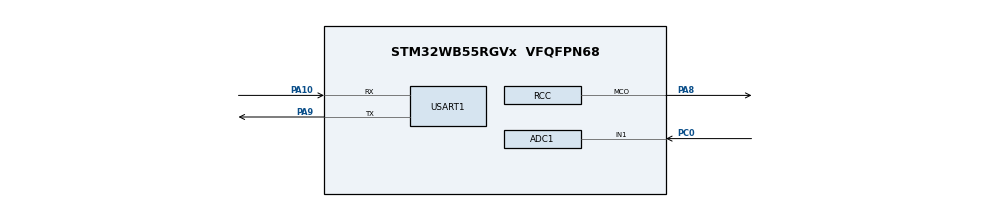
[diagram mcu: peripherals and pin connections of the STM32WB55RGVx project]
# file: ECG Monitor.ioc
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ADC1.Channel-2\#ChannelRegularConversion=ADC_CHANNEL_1
ADC1.ContinuousConvMode=ENABLE
ADC1.DataAlign=ADC_DATAALIGN_RIGHT
ADC1.NbrOfConversion=1
ADC1.NbrOfConversionFlag=1
ADC1.OffsetNumber-2\#ChannelRegularConversion=ADC_OFFSET_NONE
ADC1.Overrun=ADC_OVR_DATA_OVERWRITTEN
ADC1.Rank-2\#ChannelRegularConversion=1
ADC1.Resolution=ADC_RESOLUTION_12B
ADC1.SamplingTime-2\#ChannelRegularConversion=ADC_SAMPLETIME_2CYCLES_5
ADC1.master=1
Dma.ADC1.0.Direction=DMA_PERIPH_TO_MEMORY
Dma.ADC1.0.EventEnable=DISABLE
Dma.ADC1.0.Instance=DMA1_Channel1
Dma.ADC1.0.MemDataAlignment=DMA_MDATAALIGN_HALFWORD
Dma.ADC1.0.MemInc=DMA_MINC_ENABLE
Dma.ADC1.0.Mode=DMA_CIRCULAR
Dma.ADC1.0.PeriphDataAlignment=DMA_PDATAALIGN_HALFWORD
Dma.ADC1.0.PeriphInc=DMA_PINC_DISABLE
Dma.ADC1.0.Polarity=HAL_DMAMUX_REQ_GEN_RISING
Dma.ADC1.0.Priority=DMA_PRIORITY_LOW
Dma.ADC1.0.RequestNumber=1
Dma.ADC1.0.SignalID=NONE
Dma.ADC1.0.SyncEnable=DISABLE
Dma.ADC1.0.SyncPolarity=HAL_DMAMUX_SYNC_NO_EVENT
Dma.ADC1.0.SyncRequestNumber=1
Dma.ADC1.0.SyncSignalID=NONE
Dma.Request0=ADC1
Mcu.Family=STM32WB
Mcu.Name=STM32WB55RGVx
Mcu.Package=VFQFPN68
NVIC.ADC1_IRQn=true\:0\:0\:false\:false\:true\:true\:true\:true
NVIC.DMA1_Channel1_IRQn=true\:0\:0\:false\:false\:true\:false\:true\:true
NVIC.PriorityGroup=NVIC_PRIORITYGROUP_4
OSC_IN.Mode=HSE-External-Oscillator
OSC_IN.Signal=RCC_OSC_IN
OSC_OUT.Mode=HSE-External-Oscillator
OSC_OUT.Signal=RCC_OSC_OUT
PA10.Mode=Asynchronous
PA10.Signal=USART1_RX
PA8.Mode=Clock-out
PA8.Signal=RCC_MCO
PA9.Mode=Asynchronous
PA9.Signal=USART1_TX
PC0.Signal=ADCx_IN1
ProjectManager.HeapSize=0x200
ProjectManager.StackSize=0x400
ProjectManager.TargetToolchain=STM32CubeIDE
RCC.ADCFreq_Value=48000000
RCC.AHBFreq_Value=32000000
RCC.APB1Freq_Value=32000000
RCC.APB1TimFreq_Value=32000000
RCC.APB2Freq_Value=32000000
RCC.APB2TimFreq_Value=32000000
RCC.APB3Freq_Value=4000000
RCC.CortexFreq_Value=32000000
RCC.HCLKFreq_Value=32000000
RCC.HSE_VALUE=8000000
RCC.HSI48_VALUE=48000000
RCC.HSI_VALUE=16000000
RCC.LSE_VALUE=32768
RCC.PLLN=24
RCC.PLLR=RCC_PLLR_DIV3
RCC.PLLSAI1N=24
RCC.RCC_MCO1Source=RCC_MCO1SOURCE_HSE
RCC.SYSCLKFreq_VALUE=32000000
RCC.SYSCLKSource=RCC_SYSCLKSOURCE_PLLCLK
RCC.USBFreq_Value=48000000
RCC.VCOOutputFreq_Value=96000000
SH.ADCx_IN1.0=ADC1_IN1,IN1-Single-Ended
USART1.VirtualMode-Asynchronous=VM_ASYNC
VP_MEMORYMAP_VS_MEMORYMAP.Mode=CurAppReg
board=custom

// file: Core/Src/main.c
/* USER CODE BEGIN Header */
/**
  ******************************************************************************
  * @file           : main.c
  * @brief          : Main program body
  ******************************************************************************
  * @attention
  *
  * Copyright (c) 2026 STMicroelectronics.
  * All rights reserved.
  *
  * This software is licensed under terms that can be found in the LICENSE file
  * in the root directory of this software component.
  * If no LICENSE file comes with this software, it is provided AS-IS.
  *
  ******************************************************************************
  */
/* USER CODE END Header */
#include "main.h"

/* USER CODE BEGIN Includes */
#include <stdio.h>
/* USER CODE END Includes */

ADC_HandleTypeDef hadc1;
DMA_HandleTypeDef hdma_adc1;

UART_HandleTypeDef huart1;

/* USER CODE BEGIN PV */
uint16_t AD_RES = 0;
/* USER CODE END PV */

void SystemClock_Config(void);
void PeriphCommonClock_Config(void);
static void MX_GPIO_Init(void);
static void MX_DMA_Init(void);
static void MX_ADC1_Init(void);
static void MX_USART1_UART_Init(void);

int main(void)
{

  /* MCU Configuration--------------------------------------------------------*/

  /* Reset of all peripherals, Initializes the Flash interface and the Systick. */
  HAL_Init();

  /* Configure the system clock */
  SystemClock_Config();

  /* Configure the peripherals common clocks */
  PeriphCommonClock_Config();

  /* Initialize all configured peripherals */
  MX_GPIO_Init();
  MX_DMA_Init();
  MX_ADC1_Init();
  MX_USART1_UART_Init();
  /* USER CODE BEGIN 2 */
  HAL_ADCEx_Calibration_Start(&hadc1, 0);
  HAL_ADC_Start(&hadc1);
  /* USER CODE END 2 */

  /* Infinite loop */
  /* USER CODE BEGIN WHILE */
  while (1)
  {
	  AD_RES = HAL_ADC_GetValue(&hadc1);
	  //HAL_UART_Transmit(&huart1, &AD_RES, sizeof(AD_RES), 100);
	  HAL_Delay(1);
    /* USER CODE END WHILE */

  }
}

void SystemClock_Config(void)
{
  RCC_OscInitTypeDef RCC_OscInitStruct = {0};
  RCC_ClkInitTypeDef RCC_ClkInitStruct = {0};

  /** Configure the main internal regulator output voltage
  */
  __HAL_PWR_VOLTAGESCALING_CONFIG(PWR_REGULATOR_VOLTAGE_SCALE1);

  /** Initializes the RCC Oscillators according to the specified parameters
  * in the RCC_OscInitTypeDef structure.
  */
  RCC_OscInitStruct.OscillatorType = RCC_OSCILLATORTYPE_HSI|RCC_OSCILLATORTYPE_HSE
                              |RCC_OSCILLATORTYPE_MSI;
  RCC_OscInitStruct.HSEState = RCC_HSE_ON;
  RCC_OscInitStruct.HSIState = RCC_HSI_ON;
  RCC_OscInitStruct.MSIState = RCC_MSI_ON;
  RCC_OscInitStruct.HSICalibrationValue = RCC_HSICALIBRATION_DEFAULT;
  RCC_OscInitStruct.MSICalibrationValue = RCC_MSICALIBRATION_DEFAULT;
  RCC_OscInitStruct.MSIClockRange = RCC_MSIRANGE_6;
  RCC_OscInitStruct.PLL.PLLState = RCC_PLL_ON;
  RCC_OscInitStruct.PLL.PLLSource = RCC_PLLSOURCE_MSI;
  RCC_OscInitStruct.PLL.PLLM = RCC_PLLM_DIV1;
  RCC_OscInitStruct.PLL.PLLN = 24;
  RCC_OscInitStruct.PLL.PLLP = RCC_PLLP_DIV2;
  RCC_OscInitStruct.PLL.PLLR = RCC_PLLR_DIV3;
  RCC_OscInitStruct.PLL.PLLQ = RCC_PLLQ_DIV2;
  if (HAL_RCC_OscConfig(&RCC_OscInitStruct) != HAL_OK)
  {
    Error_Handler();
  }

  /** Configure the SYSCLKSource, HCLK, PCLK1 and PCLK2 clocks dividers
  */
  RCC_ClkInitStruct.ClockType = RCC_CLOCKTYPE_HCLK4|RCC_CLOCKTYPE_HCLK2
                              |RCC_CLOCKTYPE_HCLK|RCC_CLOCKTYPE_SYSCLK
                              |RCC_CLOCKTYPE_PCLK1|RCC_CLOCKTYPE_PCLK2;
  RCC_ClkInitStruct.SYSCLKSource = RCC_SYSCLKSOURCE_PLLCLK;
  RCC_ClkInitStruct.AHBCLKDivider = RCC_SYSCLK_DIV1;
  RCC_ClkInitStruct.APB1CLKDivider = RCC_HCLK_DIV1;
  RCC_ClkInitStruct.APB2CLKDivider = RCC_HCLK_DIV1;
  RCC_ClkInitStruct.AHBCLK2Divider = RCC_SYSCLK_DIV1;
  RCC_ClkInitStruct.AHBCLK4Divider = RCC_SYSCLK_DIV1;

  if (HAL_RCC_ClockConfig(&RCC_ClkInitStruct, FLASH_LATENCY_1) != HAL_OK)
  {
    Error_Handler();
  }
  HAL_RCC_MCOConfig(RCC_MCO1, RCC_MCO1SOURCE_HSE, RCC_MCODIV_1);
}

void PeriphCommonClock_Config(void)
{
  RCC_PeriphCLKInitTypeDef PeriphClkInitStruct = {0};

  /** Initializes the peripherals clock
  */
  PeriphClkInitStruct.PeriphClockSelection = RCC_PERIPHCLK_SMPS;
  PeriphClkInitStruct.SmpsClockSelection = RCC_SMPSCLKSOURCE_HSI;
  PeriphClkInitStruct.SmpsDivSelection = RCC_SMPSCLKDIV_RANGE1;

  if (HAL_RCCEx_PeriphCLKConfig(&PeriphClkInitStruct) != HAL_OK)
  {
    Error_Handler();
  }
}

static void MX_ADC1_Init(void)
{

  ADC_ChannelConfTypeDef sConfig = {0};

  /** Common config
  */
  hadc1.Instance = ADC1;
  hadc1.Init.ClockPrescaler = ADC_CLOCK_ASYNC_DIV1;
  hadc1.Init.Resolution = ADC_RESOLUTION_12B;
  hadc1.Init.DataAlign = ADC_DATAALIGN_RIGHT;
  hadc1.Init.ScanConvMode = ADC_SCAN_DISABLE;
  hadc1.Init.EOCSelection = ADC_EOC_SINGLE_CONV;
  hadc1.Init.LowPowerAutoWait = DISABLE;
  hadc1.Init.ContinuousConvMode = ENABLE;
  hadc1.Init.NbrOfConversion = 1;
  hadc1.Init.DiscontinuousConvMode = DISABLE;
  hadc1.Init.ExternalTrigConv = ADC_SOFTWARE_START;
  hadc1.Init.ExternalTrigConvEdge = ADC_EXTERNALTRIGCONVEDGE_NONE;
  hadc1.Init.DMAContinuousRequests = DISABLE;
  hadc1.Init.Overrun = ADC_OVR_DATA_OVERWRITTEN;
  hadc1.Init.OversamplingMode = DISABLE;
  if (HAL_ADC_Init(&hadc1) != HAL_OK)
  {
    Error_Handler();
  }

  /** Configure Regular Channel
  */
  sConfig.Channel = ADC_CHANNEL_1;
  sConfig.Rank = ADC_REGULAR_RANK_1;
  sConfig.SamplingTime = ADC_SAMPLETIME_2CYCLES_5;
  sConfig.SingleDiff = ADC_SINGLE_ENDED;
  sConfig.OffsetNumber = ADC_OFFSET_NONE;
  sConfig.Offset = 0;
  if (HAL_ADC_ConfigChannel(&hadc1, &sConfig) != HAL_OK)
  {
    Error_Handler();
  }

}

static void MX_USART1_UART_Init(void)
{

  huart1.Instance = USART1;
  huart1.Init.BaudRate = 115200;
  huart1.Init.WordLength = UART_WORDLENGTH_8B;
  huart1.Init.StopBits = UART_STOPBITS_1;
  huart1.Init.Parity = UART_PARITY_NONE;
  huart1.Init.Mode = UART_MODE_TX_RX;
  huart1.Init.HwFlowCtl = UART_HWCONTROL_NONE;
  huart1.Init.OverSampling = UART_OVERSAMPLING_16;
  huart1.Init.OneBitSampling = UART_ONE_BIT_SAMPLE_DISABLE;
  huart1.Init.ClockPrescaler = UART_PRESCALER_DIV1;
  huart1.AdvancedInit.AdvFeatureInit = UART_ADVFEATURE_NO_INIT;
  if (HAL_UART_Init(&huart1) != HAL_OK)
  {
    Error_Handler();
  }
  if (HAL_UARTEx_SetTxFifoThreshold(&huart1, UART_TXFIFO_THRESHOLD_1_8) != HAL_OK)
  {
    Error_Handler();
  }
  if (HAL_UARTEx_SetRxFifoThreshold(&huart1, UART_RXFIFO_THRESHOLD_1_8) != HAL_OK)
  {
    Error_Handler();
  }
  if (HAL_UARTEx_DisableFifoMode(&huart1) != HAL_OK)
  {
    Error_Handler();
  }

}

static void MX_DMA_Init(void)
{

  /* DMA controller clock enable */
  __HAL_RCC_DMAMUX1_CLK_ENABLE();
  __HAL_RCC_DMA1_CLK_ENABLE();

  /* DMA interrupt init */
  /* DMA1_Channel1_IRQn interrupt configuration */
  HAL_NVIC_SetPriority(DMA1_Channel1_IRQn, 0, 0);
  HAL_NVIC_EnableIRQ(DMA1_Channel1_IRQn);

}

static void MX_GPIO_Init(void)
{
  GPIO_InitTypeDef GPIO_InitStruct = {0};

  /* GPIO Ports Clock Enable */
  __HAL_RCC_GPIOC_CLK_ENABLE();
  __HAL_RCC_GPIOA_CLK_ENABLE();

  /*Configure GPIO pin : PA8 */
  GPIO_InitStruct.Pin = GPIO_PIN_8;
  GPIO_InitStruct.Mode = GPIO_MODE_AF_PP;
  GPIO_InitStruct.Pull = GPIO_NOPULL;
  GPIO_InitStruct.Speed = GPIO_SPEED_FREQ_LOW;
  GPIO_InitStruct.Alternate = GPIO_AF0_MCO;
  HAL_GPIO_Init(GPIOA, &GPIO_InitStruct);

}

void Error_Handler(void)
{
  __disable_irq();
  while (1)
  {
  }
}
